# PY32F002Axx register map
Vendor: Puya; Series: PY32F0; File version: 1.0.0
CPU: CM0+ r0p1, little endian, no MPU, no FPU, 4 interrupt priority bits
Registers are 32-bit, read-write, reset 0x0 unless marked. A register's access mark holds for its fields unless they carry their own. Offsets are from the block's base; [hi:lo] are bit positions; {n}, {i} and the like mark numbered series; 'fields as' and 'values as' point back to an identical list.

## GPIOB — General-purpose I/Os
Base 0x50000400
Same registers: GPIOF 0x50001400
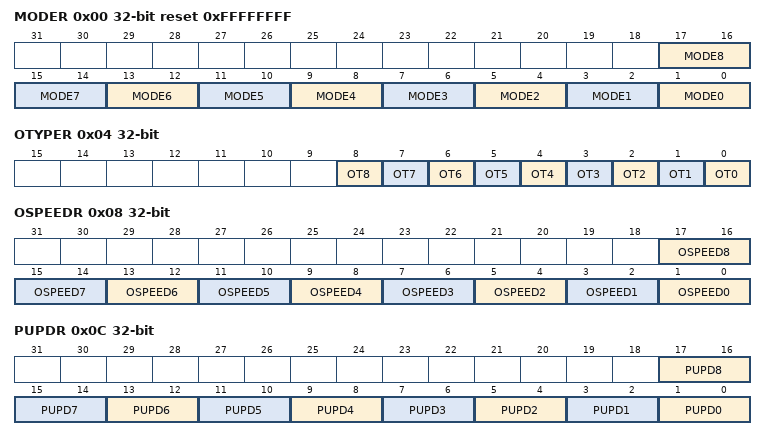
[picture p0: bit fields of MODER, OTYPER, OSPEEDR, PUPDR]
0x00 MODER reset 0xFFFFFFFF — GPIO port mode register
  [all] fields
    0=Input mode; 1=Output (General purpose output mode); 2=Alternate function mode; 3=Analog mode
  [2n+1:2n] MODE{n} (n=0..8) — Port x configuration bits (y = 0..15)
0x04 OTYPER — GPIO port output type register
  [all] fields
    0=PushPull (Output push-pull (reset state)); 1=OpenDrain (Output open-drain)
  [n] OT{n} (n=0..8) — Port x configuration bits (y = 0..15)
0x08 OSPEEDR — GPIO port output speed register
  [all] fields
    0=LowSpeed; 1=MediumSpeed; 2=HighSpeed; 3=VeryHighSpeed
  [2n+1:2n] OSPEED{n} (n=0..8) — Port x configuration bits (y = 0..15)
0x0C PUPDR — GPIO port pull-up/pull-down register
  [all] fields
    0=Floating (No pull-up, pull-down); 1=PullUp; 2=PullDown
  [2n+1:2n] PUPD{n} (n=0..8) — Port x configuration bits (y = 0..15)
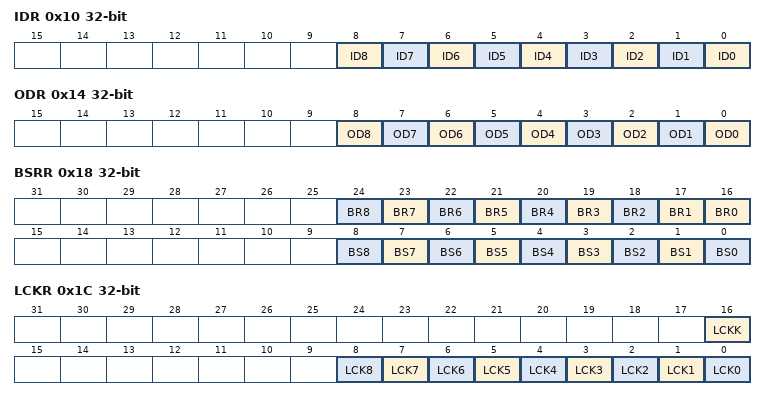
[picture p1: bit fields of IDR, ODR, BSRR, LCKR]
0x10 IDR ro — GPIO port input data register
  [all] fields
    0=Low (Input is logic low); 1=High (Input is logic high)
  [n] ID{n} (n=0..8) — Port input data (y = 0..15)
0x14 ODR — GPIO port output data register
  [all] fields
    0=Low (Set output to logic low); 1=High (Set output to logic high)
  [n] OD{n} (n=0..8) — Port output data (y = 0..15)
0x18 BSRR wo — GPIO port bit set/reset register
  [n+16] BR{n} (n=1..8) — Port x reset bit y (y = 0..15)
    1=Resets the corresponding ODx bit
  [16] BR0 — Port x set bit y (y= 0..15)
    1=Resets the corresponding ODx bit
  [n] BS{n} (n=0..8) — Port x set bit y (y= 0..15)
    1=Set (Sets the corresponding ODx bit)
0x1C LCKR — GPIO port configuration lock register
  [16] LCKK — Port x lock bit y (y= 0..15)
    0=NotActive (Port configuration lock key not active); 1=Active (Port configuration lock key active)
  [n] LCK{n} (n=0..8) — Port x lock bit y (y= 0..15)
    0=Unlocked (Port configuration not locked); 1=Locked (Port configuration locked)
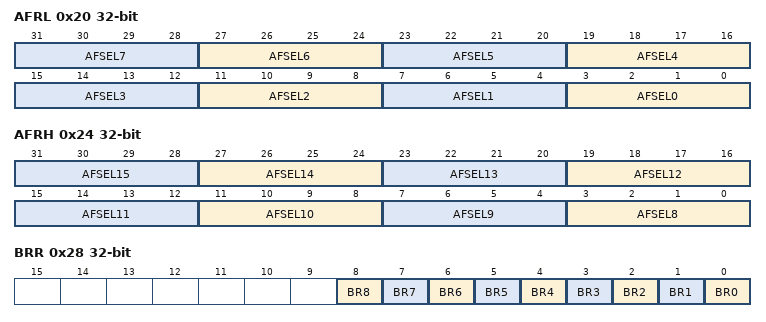
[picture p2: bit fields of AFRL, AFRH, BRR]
0x20 AFRL — GPIO alternate function low register
  [all] fields
    {v}=AF{v} (v=0..15)
  [4n+3:4n] AFSEL{n} (n=0..7) — Alternate function selection for port x bit y (y = 0..7)
0x24 AFRH — GPIO alternate function high register
  [all] fields
    {v}=AF{v} (v=0..15)
  [4n-29:4n-32] AFSEL{n} (n=8..15) — Alternate function selection for port x bit y (y = 8..15)
0x28 BRR wo — port bit reset register
  [all] fields
    0=No action on the corresponding ODx bit; 1=Reset the ODx bit
  [n] BR{n} (n=0..8) — Port Reset bit

## EXTI — External interrupt/event controller
Base 0x40021800
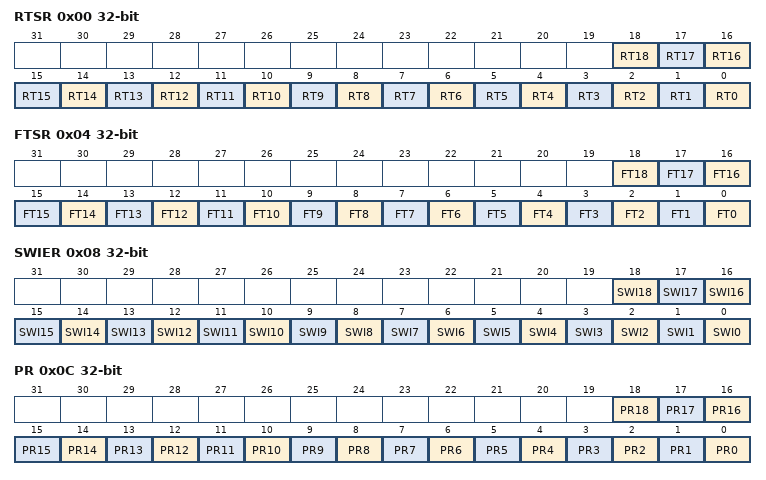
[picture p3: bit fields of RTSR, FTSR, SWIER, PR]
0x00 RTSR — EXTI rising trigger selection register
  [all] fields
    0=Disabled (Rising edge trigger is disabled); 1=Enabled (Rising edge trigger is enabled)
  [n] RT{n} (n=0..18) — Rising trigger event configuration bit of Configurable Event input
0x04 FTSR — EXTI falling trigger selection register
  [all] fields
    0=Disabled (Falling edge trigger is disabled); 1=Enabled (Falling edge trigger is enabled)
  [n] FT{n} (n=0..18) — Falling trigger event configuration bit of Configurable Event input
0x08 SWIER — EXTI software interrupt event register
  [all] fields
    on write: 1=Pend (Generates an interrupt request)
  [n] SWI{n} (n=0..18) — Rising trigger event configuration bit of Configurable Event input
0x0C PR — EXTI pending register
  [all] fields
    on read: 0=NotPending (No trigger request occurred); 1=Pending (Selected trigger request occurred) | on write: 1=Clears pending bit
  [n] PR{n} write-1-clears (n=14..18) — configurable event inputs x rising edge Pending bit.
  [13] PR13 write-1-clears — configurable event inputs x rising edge Pending bit
  [n] PR{n} write-1-clears (n=0..12) — configurable event inputs x rising edge Pending bit.
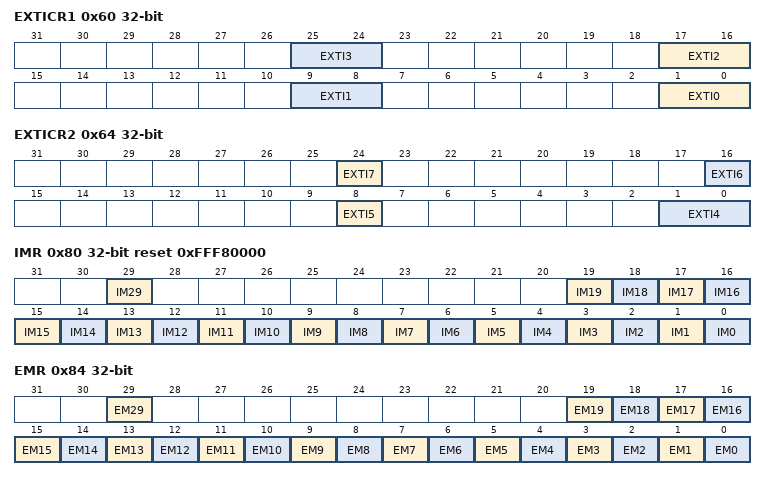
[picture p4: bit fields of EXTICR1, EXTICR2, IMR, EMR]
0x60 EXTICR1 — EXTI external interrupt selection register
  [all] fields
    0=PA (GPIO port A selected); 1=PB (GPIO port B selected); 2=PF (GPIO port F selected)
  [8n+1:8n] EXTI{n} (n=0..3) — GPIO port selection
0x64 EXTICR2 — EXTI external interrupt selection register
  [24] EXTI7 — GPIO port selection
    0=PA (GPIO port A selected); 1=PB (GPIO port B selected)
  [16] EXTI6 — GPIO port selection
    0=PA (GPIO port A selected); 1=PB (GPIO port B selected)
  [8] EXTI5 — GPIO port selection
    0=PA (GPIO port A selected); 1=PB (GPIO port B selected)
  [1:0] EXTI4 — GPIO port selection
    values as the fields of EXTICR1
0x68 EXTICR3 — EXTI external interrupt selection register
  [0] EXTI8 — GPIO port selection
    0=PA (GPIO port A selected); 1=PB (GPIO port B selected)
0x80 IMR reset 0xFFF80000 — EXTI CPU wakeup with interrupt mask register
  [all] fields
    0=Masked (Interrupt request line is masked); 1=Unmasked (Interrupt request line is unmasked)
  [29] IM29 — CPU wakeup with interrupt mask on event input
  [n] IM{n} (n=0..19) — CPU wakeup with interrupt mask on event input
0x84 EMR — EXTI CPU wakeup with event mask register
  [all] fields
    values as the fields of IMR
  [29] EM29 — CPU wakeup with event mask on event input
  [n] EM{n} (n=0..19) — CPU wakeup with event mask on event input
